# CC26x0 register map
File version: 2.3
CPU: CM3 r2p1, little endian, no MPU, no FPU, 0x3 interrupt priority bits, 0x0 interrupts
Registers are 32-bit, read-write, reset 0x0 unless marked. A register's access mark holds for its fields unless they carry their own. Offsets are from the block's base; [hi:lo] are bit positions; {n}, {i} and the like mark numbered series; 'fields as' and 'values as' point back to an identical list.

## AUX_EVCTL — AUX Event Controller
Base 0x400C5000
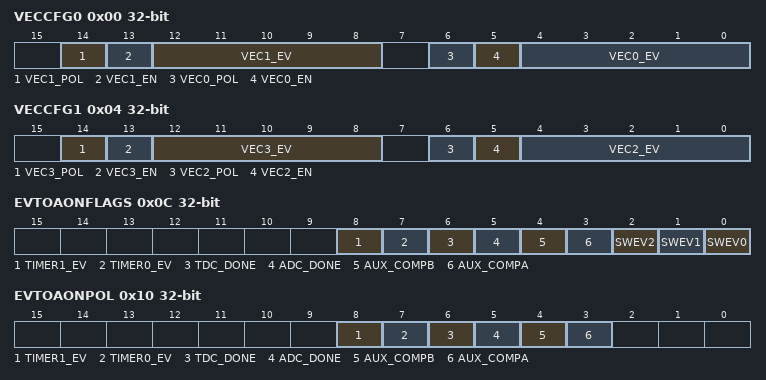
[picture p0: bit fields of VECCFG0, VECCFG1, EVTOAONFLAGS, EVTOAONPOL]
0x00 VECCFG0 — Vector Configuration 0 AUX_SCE event vectors 0 and 1 configuration
  [14] VEC1_POL, [13] VEC1_EN, [12:8] VEC1_EV, [6] VEC0_POL, [5] VEC0_EN, [4:0] VEC0_EV
0x04 VECCFG1 — Vector Configuration 1 AUX_SCE event vectors 2 and 3 configuration
  [14] VEC3_POL, [13] VEC3_EN, [12:8] VEC3_EV, [6] VEC2_POL, [5] VEC2_EN, [4:0] VEC2_EV
0x08 SCEWEVSEL — Sensor Controller Engine Wait Event Selection Event selection for the AUX_SCE WEV0, WEV1, BEV0 and BEV1 instructions
  [4:0] WEV7_EV
0x0C EVTOAONFLAGS — Events To AON Domain Flags AUX event flags going to/through the AON domain These events may be used to wake up the MCU domain. The flags may be cleared by writing 0 to these bits or writing 1 to the corresponding bits in EVTOAONFLAGSCLR.
  [8] TIMER1_EV write-0-clears, [7] TIMER0_EV write-0-clears, [6] TDC_DONE write-0-clears, [5] ADC_DONE write-0-clears, [4] AUX_COMPB write-0-clears, [3] AUX_COMPA write-0-clears, [2] SWEV2 write-0-clears, [1] SWEV1 write-0-clears, [0] SWEV0 write-0-clears
0x10 EVTOAONPOL — Events To AON Domain Polarity AUX event source polarity for the event flags going to/through the AON domain Note the inverse polarity (0 = high, 1 = low).
  [8] TIMER1_EV, [7] TIMER0_EV, [6] TDC_DONE, [5] ADC_DONE, [4] AUX_COMPB, [3] AUX_COMPA
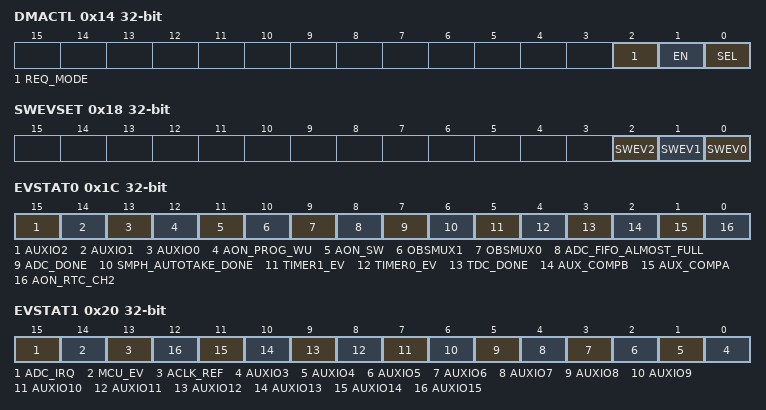
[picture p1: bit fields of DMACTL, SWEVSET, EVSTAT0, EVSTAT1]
0x14 DMACTL — Direct Memory Access Control
  [2] REQ_MODE, [1] EN, [0] SEL
0x18 SWEVSET — Software Event Set Strobes for setting software events from the AUX domain to the AON/MCU Domains The use of these events is software-defined.
  [2] SWEV2, [1] SWEV1, [0] SWEV0
0x1C EVSTAT0 ro — Event Status 0 Current event source levels, 15:0
  [15] AUXIO2, [14] AUXIO1, [13] AUXIO0, [12] AON_PROG_WU, [11] AON_SW, [10] OBSMUX1, [9] OBSMUX0, [8] ADC_FIFO_ALMOST_FULL, [7] ADC_DONE, [6] SMPH_AUTOTAKE_DONE, [5] TIMER1_EV, [4] TIMER0_EV, [3] TDC_DONE, [2] AUX_COMPB, [1] AUX_COMPA, [0] AON_RTC_CH2
0x20 EVSTAT1 ro — Event Status 1 Current event source levels, 31:16
  [15] ADC_IRQ, [14] MCU_EV, [13] ACLK_REF, [n-3] AUXIO{n} (n=3..15)
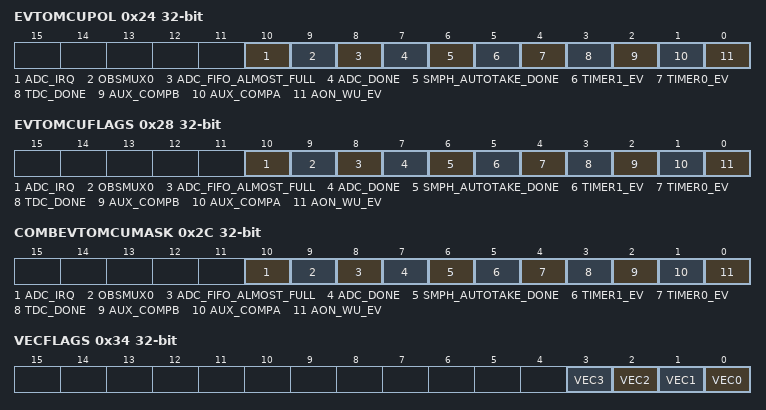
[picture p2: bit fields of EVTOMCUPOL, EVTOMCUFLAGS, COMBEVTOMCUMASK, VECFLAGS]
0x24 EVTOMCUPOL — Event To MCU Domain Polarity AUX event source polarity for the event flags to the MCU domain Note the inverse polarity (0 = high, 1 = low).
  [10] ADC_IRQ, [9] OBSMUX0, [8] ADC_FIFO_ALMOST_FULL, [7] ADC_DONE, [6] SMPH_AUTOTAKE_DONE, [5] TIMER1_EV, [4] TIMER0_EV, [3] TDC_DONE, [2] AUX_COMPB, [1] AUX_COMPA, [0] AON_WU_EV
0x28 EVTOMCUFLAGS — Events to MCU Domain Flags AUX event flags going to the MCU domain The flags may be cleared by writing 0 to these bits or writing 1 to the corresponding bits in EVTOMCUFLAGSCLR.
  [10] ADC_IRQ write-0-clears, [9] OBSMUX0 write-0-clears, [8] ADC_FIFO_ALMOST_FULL write-0-clears, [7] ADC_DONE write-0-clears, [6] SMPH_AUTOTAKE_DONE write-0-clears, [5] TIMER1_EV write-0-clears, [4] TIMER0_EV write-0-clears, [3] TDC_DONE write-0-clears, [2] AUX_COMPB write-0-clears, [1] AUX_COMPA write-0-clears, [0] AON_WU_EV write-0-clears
0x2C COMBEVTOMCUMASK — Combined Event To MCU Domain Mask Selects which of the flags In EVTOMCUFLAGS that contribute to the AUX_COMB event to the MCU domain The AUX_COMB event is asserted as long as one or more of the included event flags are set.
  fields as EVTOMCUPOL
0x34 VECFLAGS — Vector Flags If a vector flag has been set and AUX_SCE is sleeping, it will wake up and execute the vector. If multiple vectors have been set, the one with the lowest index will execute first, and the next after returning to sleep. During execution of a vector, the flag must be cleared, by writing a 1 to the corresponding bit in VECFLAGSCLR.
  [n] VEC{n} write-0-clears (n=0..3)
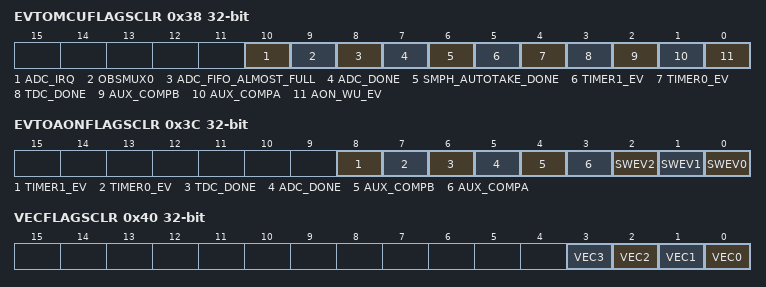
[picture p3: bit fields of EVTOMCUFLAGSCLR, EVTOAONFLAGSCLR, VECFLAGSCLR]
0x38 EVTOMCUFLAGSCLR — Events To MCU Domain Flags Clear Strobes for clearing flags in EVTOMCUFLAGS.
  fields as EVTOMCUPOL
0x3C EVTOAONFLAGSCLR — Events To AON Domain Clear Strobes for clearing flags in EVTOAONFLAGS.
  [8] TIMER1_EV, [7] TIMER0_EV, [6] TDC_DONE, [5] ADC_DONE, [4] AUX_COMPB, [3] AUX_COMPA, [2] SWEV2, [1] SWEV1, [0] SWEV0
0x40 VECFLAGSCLR — Vector Flags Clear Strobes for clearing flags in VECFLAGS.
  [n] VEC{n} (n=0..3)
